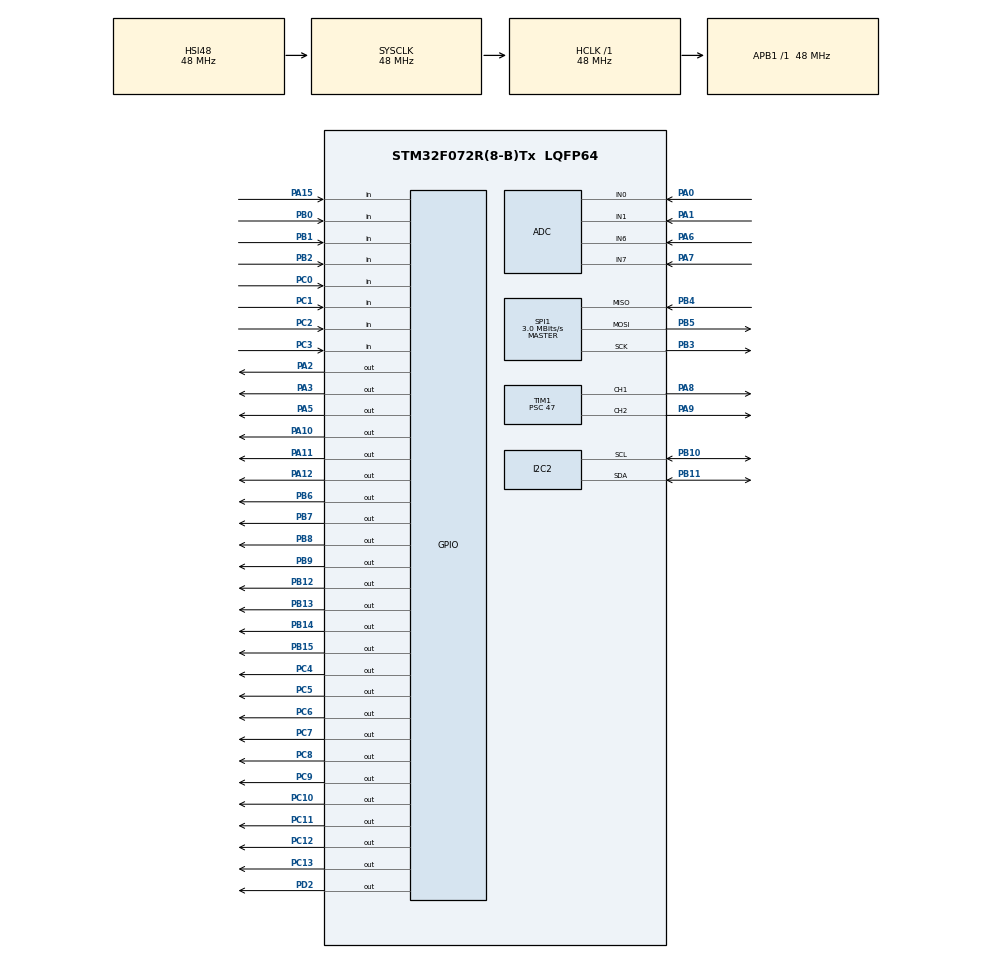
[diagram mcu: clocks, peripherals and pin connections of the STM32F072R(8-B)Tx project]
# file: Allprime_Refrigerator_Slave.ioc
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I2C2.Timing=0x20303E5D
Mcu.Family=STM32F0
Mcu.Name=STM32F072R(8-B)Tx
Mcu.Package=LQFP64
NVIC.TIM2_IRQn=true\:2\:0\:true\:false\:true\:true\:true\:true
NVIC.TIM3_IRQn=true\:0\:0\:true\:false\:true\:true\:true\:true
PA0.Mode=IN0
PA0.Signal=ADC_IN0
PA1.Mode=IN1
PA1.Signal=ADC_IN1
PA10.Signal=GPIO_Output
PA11.Signal=GPIO_Output
PA12.Signal=GPIO_Output
PA13.GPIO_Label=TMS
PA13.Mode=Serial_Wire
PA13.Signal=SYS_SWDIO
PA14.Mode=Serial_Wire
PA14.Signal=SYS_SWCLK
PA15.Signal=GPIO_Input
PA2.Signal=GPIO_Output
PA3.Signal=GPIO_Output
PA5.Signal=GPIO_Output
PA6.Mode=IN6
PA6.Signal=ADC_IN6
PA7.Mode=IN7
PA7.Signal=ADC_IN7
PA8.Signal=S_TIM1_CH1
PA9.Signal=S_TIM1_CH2
PB0.Signal=GPIO_Input
PB1.Signal=GPIO_Input
PB10.Mode=I2C
PB10.Signal=I2C2_SCL
PB11.Mode=I2C
PB11.Signal=I2C2_SDA
PB12.Signal=GPIO_Output
PB13.Signal=GPIO_Output
PB14.Signal=GPIO_Output
PB15.Signal=GPIO_Output
PB2.Signal=GPIO_Input
PB3.Mode=Full_Duplex_Master
PB3.Signal=SPI1_SCK
PB4.Mode=Full_Duplex_Master
PB4.Signal=SPI1_MISO
PB5.Mode=Full_Duplex_Master
PB5.Signal=SPI1_MOSI
PB6.Signal=GPIO_Output
PB7.Signal=GPIO_Output
PB8.Signal=GPIO_Output
PB9.Signal=GPIO_Output
PC0.Signal=GPIO_Input
PC1.Signal=GPIO_Input
PC10.Signal=GPIO_Output
PC11.Signal=GPIO_Output
PC12.Signal=GPIO_Output
PC13.Signal=GPIO_Output
PC14-OSC32_IN.Mode=LSE-External-Oscillator
PC14-OSC32_IN.Signal=RCC_OSC32_IN
PC15-OSC32_OUT.Mode=LSE-External-Oscillator
PC15-OSC32_OUT.Signal=RCC_OSC32_OUT
PC2.Signal=GPIO_Input
PC3.Signal=GPIO_Input
PC4.Signal=GPIO_Output
PC5.Signal=GPIO_Output
PC6.Signal=GPIO_Output
PC7.Signal=GPIO_Output
PC8.Signal=GPIO_Output
PC9.Signal=GPIO_Output
PD2.Signal=GPIO_Output
PF0-OSC_IN.Mode=HSE-External-Clock-Source
PF0-OSC_IN.Signal=RCC_OSC_IN
PF1-OSC_OUT.Signal=RCC_OSC_OUT
ProjectManager.HeapSize=0x200
ProjectManager.StackSize=0x400
ProjectManager.TargetToolchain=Makefile
RCC.AHBFreq_Value=48000000
RCC.APB1Freq_Value=48000000
RCC.APB1TimFreq_Value=48000000
RCC.FLatency-AdvancedSettings=FLASH_LATENCY_1
RCC.HCLKFreq_Value=48000000
RCC.PLLDivider=RCC_PREDIV_DIV2
RCC.PLLMUL=RCC_PLL_MUL12
RCC.PREFETCH_ENABLE-AdvancedSettings=1
RCC.SYSCLKFreq_VALUE=48000000
RCC.SYSCLKSource=RCC_SYSCLKSOURCE_HSI48
SH.S_TIM1_CH1.0=TIM1_CH1,Output Compare1 CH1
SH.S_TIM1_CH2.0=TIM1_CH2,Output Compare2 CH2
SPI1.BaudRatePrescaler=SPI_BAUDRATEPRESCALER_16
SPI1.CalculateBaudRate=3.0 MBits/s
SPI1.Direction=SPI_DIRECTION_2LINES
SPI1.Mode=SPI_MODE_MASTER
SPI1.VirtualType=VM_MASTER
TIM1.Channel-Output\ Compare1\ CH1=TIM_CHANNEL_1
TIM1.Channel-Output\ Compare2\ CH2=TIM_CHANNEL_2
TIM1.Period=10000
TIM1.Prescaler=47
TIM2.Period=10000
TIM2.Prescaler=47
TIM3.Period=100
TIM3.Prescaler=47
VP_TIM2_VS_ClockSourceINT.Mode=Internal
VP_TIM3_VS_ClockSourceINT.Mode=Internal
board=NUCLEO-F072RB

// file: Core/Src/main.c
/* USER CODE BEGIN Header */
/**
  ******************************************************************************
  * @file           : main.c
  * @brief          : Main program body
  ******************************************************************************
  * @attention
  *
  * Copyright (c) 2022 STMicroelectronics.
  * All rights reserved.
  *
  * This software is licensed under terms that can be found in the LICENSE file
  * in the root directory of this software component.
  * If no LICENSE file comes with this software, it is provided AS-IS.
  *
  ******************************************************************************
  */
/* USER CODE END Header */
#include "main.h"
#include "os.h"

ADC_HandleTypeDef hadc;

I2C_HandleTypeDef hi2c2;

SPI_HandleTypeDef hspi1;

TIM_HandleTypeDef htim1;
TIM_HandleTypeDef htim2;
TIM_HandleTypeDef htim3;

void SystemClock_Config(void);
static void MX_GPIO_Init(void);
static void MX_ADC_Init(void);
static void MX_I2C2_Init(void);
static void MX_SPI1_Init(void);
static void MX_TIM2_Init(void);
static void MX_TIM3_Init(void);
static void MX_TIM1_Init(void);

int main(void)
{

  /* MCU Configuration--------------------------------------------------------*/

  /* Reset of all peripherals, Initializes the Flash interface and the Systick. */
  HAL_Init();

  /* Configure the system clock */
  SystemClock_Config();

  /* Initialize all configured peripherals */
  MX_GPIO_Init();
  MX_ADC_Init();
  MX_I2C2_Init();
  MX_SPI1_Init();
  MX_TIM2_Init();
  MX_TIM3_Init();
  MX_TIM1_Init();
  /* USER CODE BEGIN 2 */
  HAL_TIM_Base_Start_IT(&htim2);
  HAL_TIM_Base_Start_IT(&htim3);
  Os_Init_Task();
  /* USER CODE END 2 */

  /* Infinite loop */
  while (1)
  {
    Os_Handler();
  }
}

void SystemClock_Config(void)
{
  RCC_OscInitTypeDef RCC_OscInitStruct = {0};
  RCC_ClkInitTypeDef RCC_ClkInitStruct = {0};

  /** Initializes the RCC Oscillators according to the specified parameters
  * in the RCC_OscInitTypeDef structure.
  */
  RCC_OscInitStruct.OscillatorType = RCC_OSCILLATORTYPE_HSI14|RCC_OSCILLATORTYPE_HSI48;
  RCC_OscInitStruct.HSI48State = RCC_HSI48_ON;
  RCC_OscInitStruct.HSI14State = RCC_HSI14_ON;
  RCC_OscInitStruct.HSI14CalibrationValue = 16;
  RCC_OscInitStruct.PLL.PLLState = RCC_PLL_NONE;
  if (HAL_RCC_OscConfig(&RCC_OscInitStruct) != HAL_OK)
  {
    Error_Handler();
  }

  /** Initializes the CPU, AHB and APB buses clocks
  */
  RCC_ClkInitStruct.ClockType = RCC_CLOCKTYPE_HCLK|RCC_CLOCKTYPE_SYSCLK
                              |RCC_CLOCKTYPE_PCLK1;
  RCC_ClkInitStruct.SYSCLKSource = RCC_SYSCLKSOURCE_HSI48;
  RCC_ClkInitStruct.AHBCLKDivider = RCC_SYSCLK_DIV1;
  RCC_ClkInitStruct.APB1CLKDivider = RCC_HCLK_DIV1;

  if (HAL_RCC_ClockConfig(&RCC_ClkInitStruct, FLASH_LATENCY_1) != HAL_OK)
  {
    Error_Handler();
  }
}

static void MX_ADC_Init(void)
{

  ADC_ChannelConfTypeDef sConfig = {0};

  /** Configure the global features of the ADC (Clock, Resolution, Data Alignment and number of conversion)
  */
  hadc.Instance = ADC1;
  hadc.Init.ClockPrescaler = ADC_CLOCK_ASYNC_DIV1;
  hadc.Init.Resolution = ADC_RESOLUTION_12B;
  hadc.Init.DataAlign = ADC_DATAALIGN_RIGHT;
  hadc.Init.ScanConvMode = ADC_SCAN_DIRECTION_FORWARD;
  hadc.Init.EOCSelection = ADC_EOC_SINGLE_CONV;
  hadc.Init.LowPowerAutoWait = DISABLE;
  hadc.Init.LowPowerAutoPowerOff = DISABLE;
  hadc.Init.ContinuousConvMode = DISABLE;
  hadc.Init.DiscontinuousConvMode = DISABLE;
  hadc.Init.ExternalTrigConv = ADC_SOFTWARE_START;
  hadc.Init.ExternalTrigConvEdge = ADC_EXTERNALTRIGCONVEDGE_NONE;
  hadc.Init.DMAContinuousRequests = DISABLE;
  hadc.Init.Overrun = ADC_OVR_DATA_PRESERVED;
  if (HAL_ADC_Init(&hadc) != HAL_OK)
  {
    Error_Handler();
  }

  /** Configure for the selected ADC regular channel to be converted.
  */
  sConfig.Channel = ADC_CHANNEL_0;
  sConfig.Rank = ADC_RANK_CHANNEL_NUMBER;
  sConfig.SamplingTime = ADC_SAMPLETIME_1CYCLE_5;
  if (HAL_ADC_ConfigChannel(&hadc, &sConfig) != HAL_OK)
  {
    Error_Handler();
  }

  /** Configure for the selected ADC regular channel to be converted.
  */
  sConfig.Channel = ADC_CHANNEL_1;
  if (HAL_ADC_ConfigChannel(&hadc, &sConfig) != HAL_OK)
  {
    Error_Handler();
  }

  /** Configure for the selected ADC regular channel to be converted.
  */
  sConfig.Channel = ADC_CHANNEL_6;
  if (HAL_ADC_ConfigChannel(&hadc, &sConfig) != HAL_OK)
  {
    Error_Handler();
  }

  /** Configure for the selected ADC regular channel to be converted.
  */
  sConfig.Channel = ADC_CHANNEL_7;
  if (HAL_ADC_ConfigChannel(&hadc, &sConfig) != HAL_OK)
  {
    Error_Handler();
  }

}

static void MX_I2C2_Init(void)
{

  hi2c2.Instance = I2C2;
  hi2c2.Init.Timing = 0x20303E5D;
  hi2c2.Init.OwnAddress1 = 0;
  hi2c2.Init.AddressingMode = I2C_ADDRESSINGMODE_7BIT;
  hi2c2.Init.DualAddressMode = I2C_DUALADDRESS_DISABLE;
  hi2c2.Init.OwnAddress2 = 0;
  hi2c2.Init.OwnAddress2Masks = I2C_OA2_NOMASK;
  hi2c2.Init.GeneralCallMode = I2C_GENERALCALL_DISABLE;
  hi2c2.Init.NoStretchMode = I2C_NOSTRETCH_DISABLE;
  if (HAL_I2C_Init(&hi2c2) != HAL_OK)
  {
    Error_Handler();
  }

  /** Configure Analogue filter
  */
  if (HAL_I2CEx_ConfigAnalogFilter(&hi2c2, I2C_ANALOGFILTER_ENABLE) != HAL_OK)
  {
    Error_Handler();
  }

  /** Configure Digital filter
  */
  if (HAL_I2CEx_ConfigDigitalFilter(&hi2c2, 0) != HAL_OK)
  {
    Error_Handler();
  }

}

static void MX_SPI1_Init(void)
{

  /* SPI1 parameter configuration*/
  hspi1.Instance = SPI1;
  hspi1.Init.Mode = SPI_MODE_MASTER;
  hspi1.Init.Direction = SPI_DIRECTION_2LINES;
  hspi1.Init.DataSize = SPI_DATASIZE_4BIT;
  hspi1.Init.CLKPolarity = SPI_POLARITY_LOW;
  hspi1.Init.CLKPhase = SPI_PHASE_1EDGE;
  hspi1.Init.NSS = SPI_NSS_SOFT;
  hspi1.Init.BaudRatePrescaler = SPI_BAUDRATEPRESCALER_16;
  hspi1.Init.FirstBit = SPI_FIRSTBIT_MSB;
  hspi1.Init.TIMode = SPI_TIMODE_DISABLE;
  hspi1.Init.CRCCalculation = SPI_CRCCALCULATION_DISABLE;
  hspi1.Init.CRCPolynomial = 7;
  hspi1.Init.CRCLength = SPI_CRC_LENGTH_DATASIZE;
  hspi1.Init.NSSPMode = SPI_NSS_PULSE_ENABLE;
  if (HAL_SPI_Init(&hspi1) != HAL_OK)
  {
    Error_Handler();
  }

}

static void MX_TIM1_Init(void)
{

  TIM_MasterConfigTypeDef sMasterConfig = {0};
  TIM_OC_InitTypeDef sConfigOC = {0};
  TIM_BreakDeadTimeConfigTypeDef sBreakDeadTimeConfig = {0};

  htim1.Instance = TIM1;
  htim1.Init.Prescaler = 47;
  htim1.Init.CounterMode = TIM_COUNTERMODE_UP;
  htim1.Init.Period = 10000;
  htim1.Init.ClockDivision = TIM_CLOCKDIVISION_DIV1;
  htim1.Init.RepetitionCounter = 0;
  htim1.Init.AutoReloadPreload = TIM_AUTORELOAD_PRELOAD_DISABLE;
  if (HAL_TIM_OC_Init(&htim1) != HAL_OK)
  {
    Error_Handler();
  }
  sMasterConfig.MasterOutputTrigger = TIM_TRGO_RESET;
  sMasterConfig.MasterSlaveMode = TIM_MASTERSLAVEMODE_DISABLE;
  if (HAL_TIMEx_MasterConfigSynchronization(&htim1, &sMasterConfig) != HAL_OK)
  {
    Error_Handler();
  }
  sConfigOC.OCMode = TIM_OCMODE_TIMING;
  sConfigOC.Pulse = 0;
  sConfigOC.OCPolarity = TIM_OCPOLARITY_HIGH;
  sConfigOC.OCNPolarity = TIM_OCNPOLARITY_HIGH;
  sConfigOC.OCFastMode = TIM_OCFAST_DISABLE;
  sConfigOC.OCIdleState = TIM_OCIDLESTATE_RESET;
  sConfigOC.OCNIdleState = TIM_OCNIDLESTATE_RESET;
  if (HAL_TIM_OC_ConfigChannel(&htim1, &sConfigOC, TIM_CHANNEL_1) != HAL_OK)
  {
    Error_Handler();
  }
  if (HAL_TIM_OC_ConfigChannel(&htim1, &sConfigOC, TIM_CHANNEL_2) != HAL_OK)
  {
    Error_Handler();
  }
  sBreakDeadTimeConfig.OffStateRunMode = TIM_OSSR_DISABLE;
  sBreakDeadTimeConfig.OffStateIDLEMode = TIM_OSSI_DISABLE;
  sBreakDeadTimeConfig.LockLevel = TIM_LOCKLEVEL_OFF;
  sBreakDeadTimeConfig.DeadTime = 0;
  sBreakDeadTimeConfig.BreakState = TIM_BREAK_DISABLE;
  sBreakDeadTimeConfig.BreakPolarity = TIM_BREAKPOLARITY_HIGH;
  sBreakDeadTimeConfig.AutomaticOutput = TIM_AUTOMATICOUTPUT_DISABLE;
  if (HAL_TIMEx_ConfigBreakDeadTime(&htim1, &sBreakDeadTimeConfig) != HAL_OK)
  {
    Error_Handler();
  }
  HAL_TIM_MspPostInit(&htim1);

}

static void MX_TIM2_Init(void)
{

  TIM_ClockConfigTypeDef sClockSourceConfig = {0};
  TIM_MasterConfigTypeDef sMasterConfig = {0};

  htim2.Instance = TIM2;
  htim2.Init.Prescaler = 47;
  htim2.Init.CounterMode = TIM_COUNTERMODE_UP;
  htim2.Init.Period = 10000;
  htim2.Init.ClockDivision = TIM_CLOCKDIVISION_DIV1;
  htim2.Init.AutoReloadPreload = TIM_AUTORELOAD_PRELOAD_DISABLE;
  if (HAL_TIM_Base_Init(&htim2) != HAL_OK)
  {
    Error_Handler();
  }
  sClockSourceConfig.ClockSource = TIM_CLOCKSOURCE_INTERNAL;
  if (HAL_TIM_ConfigClockSource(&htim2, &sClockSourceConfig) != HAL_OK)
  {
    Error_Handler();
  }
  sMasterConfig.MasterOutputTrigger = TIM_TRGO_RESET;
  sMasterConfig.MasterSlaveMode = TIM_MASTERSLAVEMODE_DISABLE;
  if (HAL_TIMEx_MasterConfigSynchronization(&htim2, &sMasterConfig) != HAL_OK)
  {
    Error_Handler();
  }

}

static void MX_TIM3_Init(void)
{

  TIM_ClockConfigTypeDef sClockSourceConfig = {0};
  TIM_MasterConfigTypeDef sMasterConfig = {0};

  htim3.Instance = TIM3;
  htim3.Init.Prescaler = 47;
  htim3.Init.CounterMode = TIM_COUNTERMODE_UP;
  htim3.Init.Period = 100;
  htim3.Init.ClockDivision = TIM_CLOCKDIVISION_DIV1;
  htim3.Init.AutoReloadPreload = TIM_AUTORELOAD_PRELOAD_DISABLE;
  if (HAL_TIM_Base_Init(&htim3) != HAL_OK)
  {
    Error_Handler();
  }
  sClockSourceConfig.ClockSource = TIM_CLOCKSOURCE_INTERNAL;
  if (HAL_TIM_ConfigClockSource(&htim3, &sClockSourceConfig) != HAL_OK)
  {
    Error_Handler();
  }
  sMasterConfig.MasterOutputTrigger = TIM_TRGO_RESET;
  sMasterConfig.MasterSlaveMode = TIM_MASTERSLAVEMODE_DISABLE;
  if (HAL_TIMEx_MasterConfigSynchronization(&htim3, &sMasterConfig) != HAL_OK)
  {
    Error_Handler();
  }

}

static void MX_GPIO_Init(void)
{
  GPIO_InitTypeDef GPIO_InitStruct = {0};

  /* GPIO Ports Clock Enable */
  __HAL_RCC_GPIOC_CLK_ENABLE();
  __HAL_RCC_GPIOF_CLK_ENABLE();
  __HAL_RCC_GPIOA_CLK_ENABLE();
  __HAL_RCC_GPIOB_CLK_ENABLE();
  __HAL_RCC_GPIOD_CLK_ENABLE();

  /*Configure GPIO pin Output Level */
  HAL_GPIO_WritePin(GPIOC, GPIO_PIN_13|GPIO_PIN_4|GPIO_PIN_5|GPIO_PIN_6
                          |GPIO_PIN_7|GPIO_PIN_8|GPIO_PIN_9|GPIO_PIN_10
                          |GPIO_PIN_11|GPIO_PIN_12, GPIO_PIN_RESET);

  /*Configure GPIO pin Output Level */
  HAL_GPIO_WritePin(GPIOA, GPIO_PIN_2|GPIO_PIN_3|GPIO_PIN_5|GPIO_PIN_10
                          |GPIO_PIN_11|GPIO_PIN_12, GPIO_PIN_RESET);

  /*Configure GPIO pin Output Level */
  HAL_GPIO_WritePin(GPIOB, GPIO_PIN_12|GPIO_PIN_13|GPIO_PIN_14|GPIO_PIN_15
                          |GPIO_PIN_6|GPIO_PIN_7|GPIO_PIN_8|GPIO_PIN_9, GPIO_PIN_RESET);

  /*Configure GPIO pin Output Level */
  HAL_GPIO_WritePin(GPIOD, GPIO_PIN_2, GPIO_PIN_RESET);

  /*Configure GPIO pins : PC13 PC4 PC5 PC6
                           PC7 PC8 PC9 PC10
                           PC11 PC12 */
  GPIO_InitStruct.Pin = GPIO_PIN_13|GPIO_PIN_4|GPIO_PIN_5|GPIO_PIN_6
                          |GPIO_PIN_7|GPIO_PIN_8|GPIO_PIN_9|GPIO_PIN_10
                          |GPIO_PIN_11|GPIO_PIN_12;
  GPIO_InitStruct.Mode = GPIO_MODE_OUTPUT_PP;
  GPIO_InitStruct.Pull = GPIO_NOPULL;
  GPIO_InitStruct.Speed = GPIO_SPEED_FREQ_LOW;
  HAL_GPIO_Init(GPIOC, &GPIO_InitStruct);

  /*Configure GPIO pins : PC0 PC1 PC2 PC3 */
  GPIO_InitStruct.Pin = GPIO_PIN_0|GPIO_PIN_1|GPIO_PIN_2|GPIO_PIN_3;
  GPIO_InitStruct.Mode = GPIO_MODE_INPUT;
  GPIO_InitStruct.Pull = GPIO_NOPULL;
  HAL_GPIO_Init(GPIOC, &GPIO_InitStruct);

  /*Configure GPIO pins : PA2 PA3 PA5 PA10
                           PA11 PA12 */
  GPIO_InitStruct.Pin = GPIO_PIN_2|GPIO_PIN_3|GPIO_PIN_4|GPIO_PIN_5|GPIO_PIN_10
                          |GPIO_PIN_11|GPIO_PIN_12;
  GPIO_InitStruct.Mode = GPIO_MODE_OUTPUT_PP;
  GPIO_InitStruct.Pull = GPIO_NOPULL;
  GPIO_InitStruct.Speed = GPIO_SPEED_FREQ_LOW;
  HAL_GPIO_Init(GPIOA, &GPIO_InitStruct);

  /*Configure GPIO pins : PB0 PB1 PB2 */
  GPIO_InitStruct.Pin = GPIO_PIN_0|GPIO_PIN_1|GPIO_PIN_2;
  GPIO_InitStruct.Mode = GPIO_MODE_INPUT;
  GPIO_InitStruct.Pull = GPIO_NOPULL;
  HAL_GPIO_Init(GPIOB, &GPIO_InitStruct);

  /*Configure GPIO pins : PB12 PB13 PB14 PB15
                           PB6 PB7 PB8 PB9 */
  GPIO_InitStruct.Pin = GPIO_PIN_12|GPIO_PIN_13|GPIO_PIN_14|GPIO_PIN_15
                          |GPIO_PIN_6|GPIO_PIN_7|GPIO_PIN_8|GPIO_PIN_9;
  GPIO_InitStruct.Mode = GPIO_MODE_OUTPUT_PP;
  GPIO_InitStruct.Pull = GPIO_NOPULL;
  GPIO_InitStruct.Speed = GPIO_SPEED_FREQ_LOW;
  HAL_GPIO_Init(GPIOB, &GPIO_InitStruct);

  /*Configure GPIO pin : PA15 */
  GPIO_InitStruct.Pin = GPIO_PIN_15;
  GPIO_InitStruct.Mode = GPIO_MODE_INPUT;
  GPIO_InitStruct.Pull = GPIO_NOPULL;
  HAL_GPIO_Init(GPIOA, &GPIO_InitStruct);

  /*Configure GPIO pin : PD2 */
  GPIO_InitStruct.Pin = GPIO_PIN_2;
  GPIO_InitStruct.Mode = GPIO_MODE_OUTPUT_PP;
  GPIO_InitStruct.Pull = GPIO_NOPULL;
  GPIO_InitStruct.Speed = GPIO_SPEED_FREQ_LOW;
  HAL_GPIO_Init(GPIOD, &GPIO_InitStruct);

}

void Error_Handler(void)
{
  __disable_irq();
  while (1)
  {
  }
}
